# BAT32G133B register map
Vendor: CMS; Series: BAT32G133B; File version: 1.2
CPU: CM0+ r0p1, little endian, no MPU, no FPU, VTOR, 2 interrupt priority bits
Registers are 8-bit, read-write, reset 0x0 unless marked. A register's access mark holds for its fields unless they carry their own. Offsets are from the block's base; [hi:lo] are bit positions; {n}, {i} and the like mark numbered series; 'fields as' and 'values as' point back to an identical list.

## RST — Reset Function
Base 0x40020420
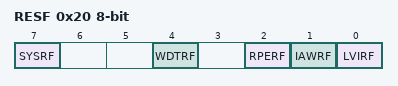
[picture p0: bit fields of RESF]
0x20 RESF ro — Reset flag register
  [all] fields
    0=NONE (Internal reset request is not generated, or the RESF register is cleared.); 1=DONE (Internal reset request is generated.)
  [7] SYSRF read-clears — Internal reset request by system reset request(AIRCR.SYSRESETREQ)
  [4] WDTRF read-clears — Internal reset request by watchdog timer(WDT)
  [2] RPERF read-clears — Internal reset request by RAM parity
  [1] IAWRF read-clears — Internal reset request by illegal-memory access
  [0] LVIRF read-clears — Internal reset request by voltage detector

## LVD — Voltage detector
Base 0x40020440
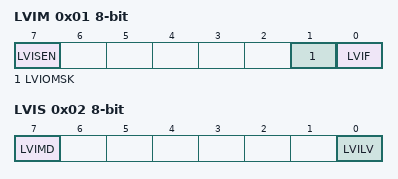
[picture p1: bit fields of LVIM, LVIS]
0x01 LVIM — Voltage detection register
  [7] LVISEN ro — Enable rewritting LVIS register
    0=Disable (Disabling of rewriting the LVIS register); 1=Enable (Enabling of rewriting the LVIS register)
  [1] LVIOMSK ro — Mask status flag of LVD output
    0=Invalid (Mask of LVD output is invalid); 1=Valid (Mask of LVD output is valid)
  [0] LVIF ro — Voltage detection flag
    0=GE (Supply voltage (VDD) greater or equal to detection voltage (VLVD), or when LVD is off); 1=LT (Supply voltage (VDD) less than detection voltage (VLVD))
0x02 LVIS — Voltage detection level register
  [7] LVIMD — Operation mode of voltage detection
    0=IRQ (interrupt mode); 1=reset mode
  [0] LVILV — LVD detection level
    0=High-voltage detection level (VLVDH); 1=Low (Low-voltage detection level (VLVDL or VLVD))

## PORT — Port functions
Base 0x40040000
0x30 PU0 (reset mask 0x1) — Pull-up resistor option register 0
0x31 PU1 (reset mask 0x3) — Pull-up resistor option register 1
0x32 PU2 (reset mask 0x7F) — Pull-up resistor option register 2
0x33 PU3 — Pull-up resistor option register 3
{0x40+i} PD{i} (i=0..3) — Pull-down resistor option register {i}
0x50 POM0 (reset mask 0x6) — Port output mode register 0
0x51 POM1 (reset mask 0xF) — Port output mode register 1
0x52 POM2 (reset mask 0x7F) — Port output mode register 2
0x53 POM3 — Port output mode register 3
0x60 PMC0 reset 0xFF — Port mode control register 0
0x61 PMC1 reset 0xFF — Port mode control register 1
0x62 PMC2 reset 0xFC (reset mask 0x7F) — Port mode control register 2
0x63 PMC3 reset 0x1F — Port mode control register 3
{0x80+i} PSET{i} (i=0..3) — Port set register {i}
{0x90+i} PCLR{i} (i=0..3) — Port clear register {i}
{0xA0+i} PREAD{i} (i=0..3) — Port read register {i}
0x300 P0 (reset mask 0x7) — Port register 0
0x301 P1 (reset mask 0xF) — Port register 1
0x302 P2 (reset mask 0x7F) — Port register 2
0x303 P3 (reset mask 0x3) — Port register 3
0x320 PM0 reset 0xFF (reset mask 0x7) — Port mode register 0
0x321 PM1 reset 0xFF (reset mask 0xF) — Port mode register 1
0x322 PM2 reset 0xFF (reset mask 0x7F) — Port mode register 2
0x323 PM3 reset 0xFF — Port mode register 3
0x800 P00CFG — P00 Peripheral Function configuration register
  [5:0] P00CFG
    0=GPIO (Port used as GPIO)
0x802 P01CFG — P01 Peripheral Function configuration register
  [5:0] P01CFG
    0=GPIO (Port used as GPIO); {v}=INTP{v-2} (Port used as INTP{v-2}) (v=2..5); {v}=TI{v-6:02} (Port used as TI{v-6:02}) (v=6..9); {v}=TI{v} (Port used as TI{v}) (v=10..13); {v}=TO{v-14:02} (Port used as TO{v-14:02}) (v=14..17); {v}=TO{v-8} (Port used as TO{v-8}) (v=18..21); 22=SCLA0 (Port used as SCLA0); 23=SDAA0 (Port used as SDAA0); 24=CLKBUZ0 (Port used as CLKBUZ0); 25=CLKBUZ1 (Port used as CLKBUZ1); 26=CMPOUT0 (Port used as CMPOUT0); 27=CMPOUT1 (Port used as CMPOUT1); 28=RTC1HZ (Port used as RTC1HZ); 31=SS00 (Port used as SS00); 32=SCLK00/SCL00 (Port used as SCLK00/SCL00); 33=SCLK01/SCL01 (Port used as SCLK01/SCL01); 34=SCLK10/SCL10 (Port used as SCLK10/SCL10); 35=SCLK11/SCL11 (Port used as SCLK11/SCL11); 36=SCLK20/SCL20 (Port used as SCLK20/SCL20); 37=SCLK21/SCL21 (Port used as SCLK21/SCL21); 38=SDI00/SDAI00/RxD0 (Port used as SDI00/SDAI00/RxD0); 39=SDI01/SDAI01 (Port used as SDI01/SDAI01); 40=SDI10/SDAI10/RxD1 (Port used as SDI10/SDAI10/RxD1); 41=SDI11/SDAI11 (Port used as SDI11/SDAI11); 42=SDI20/SDAI20/RxD2 (Port used as SDI20/SDAI20/RxD2); 43=SDI21/SDAI21 (Port used as SDI21/SDAI21); 44=SDO00/TxD0 (Port used as SDO00/TxD0); 45=SDO01 (Port used as SDO01); 46=SDO10/TxD1 (Port used as SDO10/TxD1); 47=SDO11 (Port used as SDO11); 48=SDO20/TxD2 (Port used as SDO20/TxD2); 49=SDO21 (Port used as SDO21); 50=SDAO00 (Port used as SDAO00); 51=SDAO01 (Port used as SDAO01); 52=SDAO10 (Port used as SDAO10); 53=SDAO11 (Port used as SDAO11); 54=SDAO20 (Port used as SDAO20); 55=SDAO21 (Port used as SDAO21)
0x804 P02CFG — P02 Peripheral Function configuration register
  [5:0] P02CFG
    values as P01CFG.P01CFG
{0x7FC+2i} P{i}CFG (i=10..13) — P{i} Peripheral Function configuration register
  [5:0] P{i}CFG
    values as P01CFG.P01CFG
{0x7F8+2i} P{i}CFG (i=20..26) — P{i} Peripheral Function configuration register
  fields as P10CFG
{0x7F4+2i} P{i}CFG (i=30..37) — P{i} Peripheral Function configuration register
  fields as P10CFG
0x87B PMS (reset mask 0x1) — Port mode select register

## Notices in the file
Copyright (C) 2012-2014 ARM Limited. All rights reserved.
Purpose: System Viewer Description (SVD) Example (Schema Version 1.1)
This is a description of a none-existent and incomplete device
for demonstration purposes only.
Redistribution and use in source and binary forms, with or without
modification, are permitted provided that the following conditions are met:
- Redistributions of source code must retain the above copyright
notice, this list of conditions and the following disclaimer.
- Redistributions in binary form must reproduce the above copyright
notice, this list of conditions and the following disclaimer in the
documentation and/or other materials provided with the distribution.
- Neither the name of ARM nor the names of its contributors may be used
to endorse or promote products derived from this software without
specific prior written permission.
THIS SOFTWARE IS PROVIDED BY THE COPYRIGHT HOLDERS AND CONTRIBUTORS "AS IS"
AND ANY EXPRESS OR IMPLIED WARRANTIES, INCLUDING, BUT NOT LIMITED TO, THE
IMPLIED WARRANTIES OF MERCHANTABILITY AND FITNESS FOR A PARTICULAR PURPOSE
ARE DISCLAIMED. IN NO EVENT SHALL COPYRIGHT HOLDERS AND CONTRIBUTORS BE
LIABLE FOR ANY DIRECT, INDIRECT, INCIDENTAL, SPECIAL, EXEMPLARY, OR
CONSEQUENTIAL DAMAGES (INCLUDING, BUT NOT LIMITED TO, PROCUREMENT OF
SUBSTITUTE GOODS OR SERVICES; LOSS OF USE, DATA, OR PROFITS; OR BUSINESS
INTERRUPTION) HOWEVER CAUSED AND ON ANY THEORY OF LIABILITY, WHETHER IN
CONTRACT, STRICT LIABILITY, OR TORT (INCLUDING NEGLIGENCE OR OTHERWISE)
ARISING IN ANY WAY OUT OF THE USE OF THIS SOFTWARE, EVEN IF ADVISED OF THE
POSSIBILITY OF SUCH DAMAGE.
